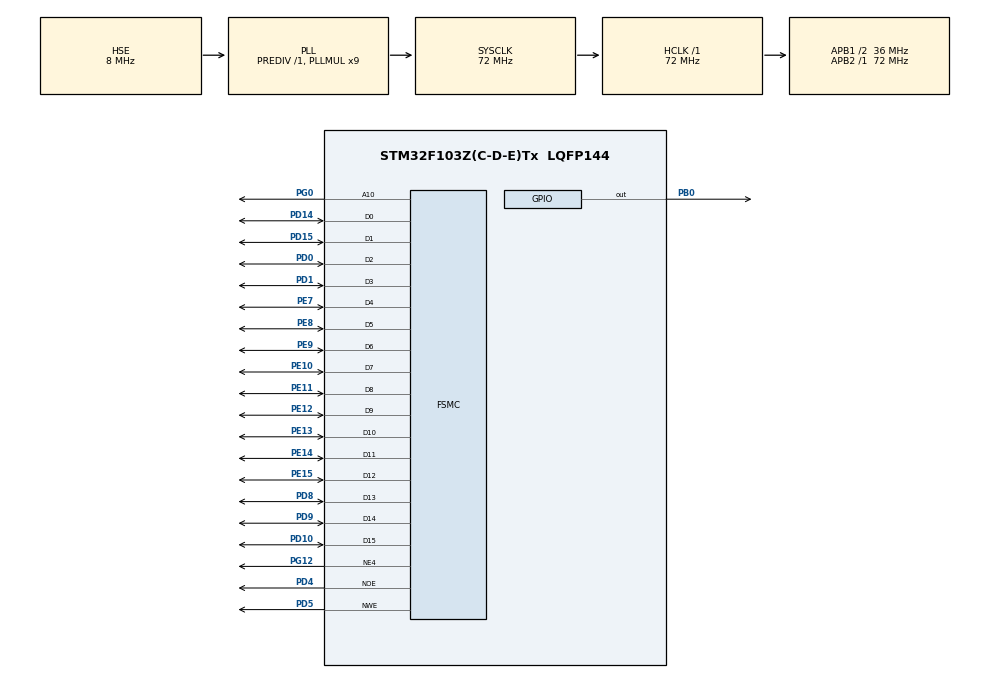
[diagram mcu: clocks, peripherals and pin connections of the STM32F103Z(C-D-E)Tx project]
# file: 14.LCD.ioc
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Mcu.Family=STM32F1
RCC.PLLSourceVirtual=RCC_PLLSOURCE_HSE
FSMC.AddressSetupTime4=1
SH.FSMC_D12_DA12.0=FSMC_D12,16b-d4
SH.FSMC_D1_DA1.0=FSMC_D1,16b-d4
FSMC.ExtendedAddressSetupTime4=0
FSMC.ExtendedMode4=FSMC_EXTENDED_MODE_ENABLE
SH.FSMC_NWE.0=FSMC_NWE,Lcd4
PG0.Signal=FSMC_A10
SH.FSMC_D0_DA0.0=FSMC_D0,16b-d4
PD1.Signal=FSMC_D3_DA3
SH.FSMC_D9_DA9.0=FSMC_D9,16b-d4
PD9.Signal=FSMC_D14_DA14
PD5.Signal=FSMC_NWE
RCC.APB1CLKDivider=RCC_HCLK_DIV2
RCC.SYSCLKSource=RCC_SYSCLKSOURCE_PLLCLK
ProjectManager.StackSize=0x400
SH.FSMC_D8_DA8.0=FSMC_D8,16b-d4
PB0.GPIO_Speed=GPIO_SPEED_FREQ_HIGH
PD10.Signal=FSMC_D15_DA15
PA13.Signal=SYS_JTMS-SWDIO
FSMC.DataSetupTime4=15
ProjectManager.TargetToolchain=STM32CubeIDE
PB0.PinState=GPIO_PIN_SET
RCC.HCLKFreq_Value=72000000
PD4.Signal=FSMC_NOE
RCC.APB2TimFreq_Value=72000000
PD0.Signal=FSMC_D2_DA2
PD8.Signal=FSMC_D13_DA13
OSC_IN.Signal=RCC_OSC_IN
RCC.USBFreq_Value=72000000
OSC_OUT.Mode=HSE-External-Oscillator
SH.FSMC_A10.0=FSMC_A10,A10_4
PE11.Signal=FSMC_D8_DA8
OSC_OUT.Signal=RCC_OSC_OUT
FSMC.ExtendedDataSetupTime4=3
RCC.AHBFreq_Value=72000000
SH.FSMC_D7_DA7.0=FSMC_D7,16b-d4
board=custom
PG12.Mode=NorPsramChipSelect4_4
RCC.PLLMUL=RCC_PLL_MUL9
RCC.APB2Freq_Value=72000000
PE14.Signal=FSMC_D11_DA11
PE15.Signal=FSMC_D12_DA12
PE13.Signal=FSMC_D10_DA10
SH.FSMC_D14_DA14.0=FSMC_D14,16b-d4
SH.FSMC_D10_DA10.0=FSMC_D10,16b-d4
PE8.Signal=FSMC_D5_DA5
PE9.Signal=FSMC_D6_DA6
PA14.Mode=Serial_Wire
SH.FSMC_D6_DA6.0=FSMC_D6,16b-d4
PA13.Mode=Serial_Wire
PE10.Signal=FSMC_D7_DA7
SH.FSMC_D5_DA5.0=FSMC_D5,16b-d4
Mcu.Name=STM32F103Z(C-D-E)Tx
PE12.Signal=FSMC_D9_DA9
SH.FSMC_D4_DA4.0=FSMC_D4,16b-d4
PD14.Signal=FSMC_D0_DA0
RCC.SYSCLKFreq_VALUE=72000000
Mcu.Package=LQFP144
OSC_IN.Mode=HSE-External-Oscillator
SH.FSMC_D13_DA13.0=FSMC_D13,16b-d4
SH.FSMC_D15_DA15.0=FSMC_D15,16b-d4
PA14.Signal=SYS_JTCK-SWCLK
ProjectManager.HeapSize=0x200
SH.FSMC_D11_DA11.0=FSMC_D11,16b-d4
SH.FSMC_NOE.0=FSMC_NOE,Lcd4
NVIC.PriorityGroup=NVIC_PRIORITYGROUP_4
SH.FSMC_D3_DA3.0=FSMC_D3,16b-d4
RCC.APB1TimFreq_Value=72000000
SH.FSMC_D2_DA2.0=FSMC_D2,16b-d4
PE7.Signal=FSMC_D4_DA4
RCC.APB1Freq_Value=36000000
PB0.Signal=GPIO_Output
PD15.Signal=FSMC_D1_DA1
PB0.GPIO_PuPd=GPIO_PULLUP
PG12.Signal=FSMC_NE4

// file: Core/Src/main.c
/* USER CODE BEGIN Header */
/**
 ******************************************************************************
 * @file           : main.c
 * @brief          : Main program body
 ******************************************************************************
 * @attention
 *
 * <h2><center>&copy; Copyright (c) 2021 STMicroelectronics.
 * All rights reserved.</center></h2>
 *
 * This software component is licensed by ST under BSD 3-Clause license,
 * the "License"; You may not use this file except in compliance with the
 * License. You may obtain a copy of the License at:
 *                        opensource.org/licenses/BSD-3-Clause
 *
 ******************************************************************************
 */
/* USER CODE END Header */
#include "main.h"
#include "gpio.h"
#include "fsmc.h"

/* USER CODE BEGIN Includes */
#include "lcd.h"
/* USER CODE END Includes */

void SystemClock_Config(void);

int main(void) {

	/* MCU Configuration--------------------------------------------------------*/

	/* Reset of all peripherals, Initializes the Flash interface and the Systick. */
	HAL_Init();

	/* Configure the system clock */
	SystemClock_Config();

	/* Initialize all configured peripherals */
	MX_GPIO_Init();
	MX_FSMC_Init();
	/* USER CODE BEGIN 2 */
	LCD_Init();
	LCD_Clear(WHITE);
	POINT_COLOR = RED;
	/* USER CODE END 2 */

	/* Infinite loop */
	while (1) {

		/* USER CODE BEGIN 3 */
		LCD_ShowString(10, 30, 240, 60, 60, "STM32F103ZET6");
		LCD_ShowString(30, 80, 200, 16, 16, "This is a test");
		LCD_ShowString(30, 110, 200, 16, 16, "Auth:Aaron");
		LCD_ShowString(54, 140, 200, 16, 16, "2021/05/04");

	}
	/* USER CODE END 3 */
}

void SystemClock_Config(void) {
	RCC_OscInitTypeDef RCC_OscInitStruct = { 0 };
	RCC_ClkInitTypeDef RCC_ClkInitStruct = { 0 };

	/** Initializes the RCC Oscillators according to the specified parameters
	 * in the RCC_OscInitTypeDef structure.
	 */
	RCC_OscInitStruct.OscillatorType = RCC_OSCILLATORTYPE_HSE;
	RCC_OscInitStruct.HSEState = RCC_HSE_ON;
	RCC_OscInitStruct.HSEPredivValue = RCC_HSE_PREDIV_DIV1;
	RCC_OscInitStruct.HSIState = RCC_HSI_ON;
	RCC_OscInitStruct.PLL.PLLState = RCC_PLL_ON;
	RCC_OscInitStruct.PLL.PLLSource = RCC_PLLSOURCE_HSE;
	RCC_OscInitStruct.PLL.PLLMUL = RCC_PLL_MUL9;
	if (HAL_RCC_OscConfig(&RCC_OscInitStruct) != HAL_OK) {
		Error_Handler();
	}
	/** Initializes the CPU, AHB and APB buses clocks
	 */
	RCC_ClkInitStruct.ClockType = RCC_CLOCKTYPE_HCLK | RCC_CLOCKTYPE_SYSCLK
			| RCC_CLOCKTYPE_PCLK1 | RCC_CLOCKTYPE_PCLK2;
	RCC_ClkInitStruct.SYSCLKSource = RCC_SYSCLKSOURCE_PLLCLK;
	RCC_ClkInitStruct.AHBCLKDivider = RCC_SYSCLK_DIV1;
	RCC_ClkInitStruct.APB1CLKDivider = RCC_HCLK_DIV2;
	RCC_ClkInitStruct.APB2CLKDivider = RCC_HCLK_DIV1;

	if (HAL_RCC_ClockConfig(&RCC_ClkInitStruct, FLASH_LATENCY_2) != HAL_OK) {
		Error_Handler();
	}
}

void Error_Handler(void) {
	__disable_irq();
	while (1) {
	}
}

/************************ (C) COPYRIGHT STMicroelectronics *****END OF FILE****/
